AUTOSAR XML (schema 4-2-2)
package /AUTOSAR_BswM/SwComponentTypes
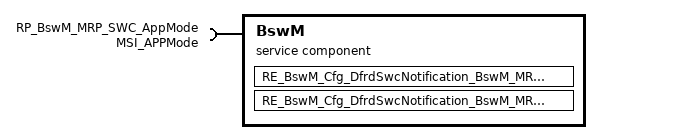
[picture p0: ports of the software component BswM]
  service sw component type BswM
    require port RP_BswM_MRP_SWC_AppMode: mode-switch-receiver-com-spec=supports-asynchronous-mode-switch=true, required-interface=MSI_APPMode
    behavior IB_BswM: data-type-mapping=[ECUM_STATE_Mapping, ComMModeMapping, DTS_DcmEcuReset, DTS_DcmDiagnosticSessionControl]
      swc mode switch event MSE_BswM_Cfg_DfrdSwcNotification_BswM_MRP_SWC_AppMode_ECUM_STATE_APP_RUN: start-on-event=RE_BswM_Cfg_DfrdSwcNotification_BswM_MRP_SWC_AppMode_ECUM_STATE_APP_RUN, activation=ON-ENTRY, mode=RP_BswM_MRP_SWC_AppMode.MDGP_APPMode.ECUM_STATE_APP_RUN
      swc mode switch event MSE_BswM_Cfg_DfrdSwcNotification_BswM_MRP_SWC_AppMode_ECUM_STATE_POST_RUN: start-on-event=RE_BswM_Cfg_DfrdSwcNotification_BswM_MRP_SWC_AppMode_ECUM_STATE_POST_RUN, activation=ON-ENTRY, mode=RP_BswM_MRP_SWC_AppMode.MDGP_APPMode.ECUM_STATE_POST_RUN
      runnable RE_BswM_Cfg_DfrdSwcNotification_BswM_MRP_SWC_AppMode_ECUM_STATE_APP_RUN: can-be-invoked-concurrently=true, mode-access-point=RP_BswM_MRP_SWC_AppMode.MDGP_APPMode, symbol=BswM_Cfg_DfrdSwcNotification_BswM_MRP_SWC_AppMode_ECUM_STATE_APP_RUN
      runnable RE_BswM_Cfg_DfrdSwcNotification_BswM_MRP_SWC_AppMode_ECUM_STATE_POST_RUN: can-be-invoked-concurrently=true, mode-access-point=RP_BswM_MRP_SWC_AppMode.MDGP_APPMode, symbol=BswM_Cfg_DfrdSwcNotification_BswM_MRP_SWC_AppMode_ECUM_STATE_POST_RUN
package /AUTOSAR_BswM/SwcImplementations
  swc implementation SWCIMPL_BswM: programming-language=C, sw-version=1.0.0, swc-bsw-mapping=BswM, behavior=IB_BswM
    code-descriptors:
      code CodeDescriptor: artifact-descriptors=autosar-engineering-object={short-label=ArEngObj, category=SWSRC}
package /AUTOSAR_BswM/SwcBswMappings
  swc bsw mapping BswM: bsw-behavior=IB_BswM, swc-behavior=IB_BswM
